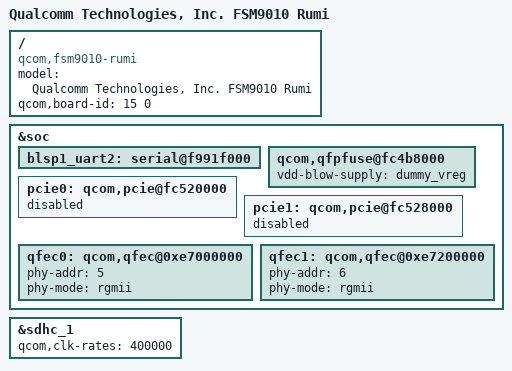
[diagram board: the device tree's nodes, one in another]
/* Copyright (c) 2014-2015, The Linux Foundation. All rights reserved.
 *
 * This program is free software; you can redistribute it and/or modify
 * it under the terms of the GNU General Public License version 2 and
 * only version 2 as published by the Free Software Foundation.
 *
 * This program is distributed in the hope that it will be useful,
 * but WITHOUT ANY WARRANTY; without even the implied warranty of
 * MERCHANTABILITY or FITNESS FOR A PARTICULAR PURPOSE.  See the
 * GNU General Public License for more details.
 */

/dts-v1/;

#include "fsm9010.dtsi"

/ {
	model = "Qualcomm Technologies, Inc. FSM9010 Rumi";
	compatible = "qcom,fsm9010-rumi", "qcom,fsm9010", "qcom,rumi";
	qcom,board-id = <15 0>;
};

&soc {
	blsp1_uart2: serial@f991f000 {
		status = "ok";
	};

	qcom,qfpfuse@fc4b8000 {
		status = "ok";
		vdd-blow-supply = <&dummy_vreg>;
	};

	pcie0: qcom,pcie@fc520000 {
		status = "disabled";
	};

	pcie1: qcom,pcie@fc528000 {
		status = "disabled";
	};

	qfec0: qcom,qfec@0xe7000000 {
		phy-addr = <5>;
		phy-mode = "rgmii";
		status = "ok";
	};

	qfec1: qcom,qfec@0xe7200000 {
		phy-addr = <6>;
		phy-mode = "rgmii";
		status = "ok";
	};

};

&sdhc_1 {
	status = "ok";
	qcom,clk-rates = <400000>;
};

